# STM32MP23_CM33 register map
File version: 1.2
CPU: CM33 r0p1, little endian, MPU, FPU, vendor SysTick, 8 interrupt priority bits
Registers are 32-bit, read-write, reset 0x0 unless marked. A register's access mark holds for its fields unless they carry their own. Offsets are from the block's base; [hi:lo] are bit positions; 'fields as' and 'values as' point back to an identical list.

## USB3DR (part 3 of 4) — USB3DR register block
Base 0x48300000
Same registers: USB3DR_S 0x58300000
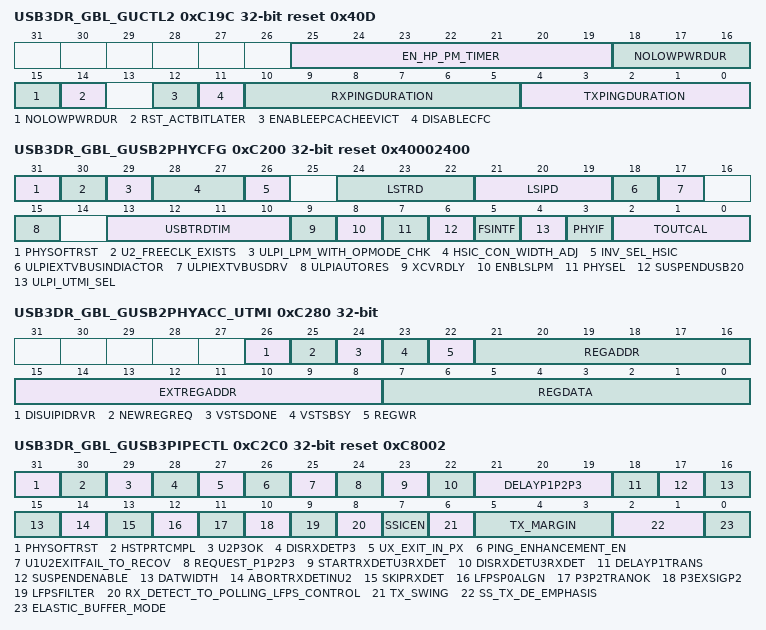
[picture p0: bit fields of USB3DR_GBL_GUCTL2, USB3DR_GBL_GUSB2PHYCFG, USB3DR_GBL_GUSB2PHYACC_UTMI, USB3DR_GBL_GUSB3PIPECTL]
0xC19C USB3DR_GBL_GUCTL2 reset 0x40D — USB3DR global user control register 2
  [25:19] EN_HP_PM_TIMER — This register field is used to set new HP and PM timers. - To enable PM timer, set GUCTL2[19] bit as 1. - To enable HP timer, set GUCTL2[20] bit as 1. Default value is 4 us, when new HP timer is enabled default value is 11 us. Use GUCTL2[25:21] to specify HP timer value in microseconds.
  [18:15] NOLOWPWRDUR — No low power duration (NOLOWPWRDUR) This bit is applicable for Device mode only and is ignored in Host mode. After starting a transfer on an ESS ISOC endpoint, the application must program these bits. Each count represents the duration in terms of milliseconds. For example, a value of 3 represents 3ms.
  [14] RST_ACTBITLATER — Enable clearing of the command active bit for the ENDXFER command after the command execution is completed. This bit is valid in device mode only.
  [12] ENABLEEPCACHEEVICT — Enable evicting endpoint cache after flow control for bulk endpoints. In 3.00a release, a performance enhancement was done to keep the non-stream capable bulk IN endpoint in cache after flow control. Setting this bit disables this enhancement. Thismust be set only for debug purpose.
  [11] DISABLECFC — Disable xHCI errata feature contiguous frame ID capability This field controls the xHCI errata feature contiguous FrameID capability. When set, the xHCI HCCPARAMS1 bit 11 is set to 0 indicating that CFC is not supported. Disable this feature only if the application cannot tolerate missed service error events for Isoc transfers, and the system latencies are large enough to cause missed service errors even if the software is following the isochronous thresholding rules.
  [10:5] RXPINGDURATION — Receive ping maximum duration This field is relevant in Host mode and controls the maximum duration of received LFPS to be treated as a ping LFPS. The maximum duration of the ping LFPS is controlled by programming this value by steps of 8ns. Example: A value of 32 indicates 256ns.
  [4:0] TXPINGDURATION — Transmit ping maximum duration This field is relevant in Device mode and controls the maximum duration for which the controller should instruct the PHY to transmit a ping LFPS. The duration of the ping LFPS is controlled by programming this value by steps of 8ns. Example: A value of 13 indicates 104ns.
0xC200 USB3DR_GBL_GUSB2PHYCFG reset 0x40002400 — USB3DR global USB2 PHY configuration register
  [31] PHYSOFTRST — UTMI PHY soft reset (PHYSoftRst) Causes the usb2phy_reset signal to be asserted to reset a UTMI PHY. Not applicable to ULPI because ULPI PHYs are reset via their FunctionControl.Reset register, and the core automatically writes to this register when the core is reset (vcc_reset_n, USBCMD.HCRST, DCTL.SoftReset, or GCTL.SoftReset)
  [30] U2_FREECLK_EXISTS — U2_FREECLK_EXISTS Specifies whether the USB 2.0 PHY provides a free-running PHY clock, which is active when the clock control input is active. If the USB 2.0 PHY provides a free-running PHY clock, it must be connected to the utmi_clk[0] input. The remaining utmi_clk[n] must be connected to the respective port clocks. The core uses the Port-0 clock for generating the internal mac2 clock. Note: When the core is configured as device-only (USB3DR_MODE=0), do not set this bit to 1.
    0=USB 2.0 free clock does not exist; 1=USB 2.0 free clock exists
  [29] ULPI_LPM_WITH_OPMODE_CHK — ULPI_LPM_WITH_OPMODE_CHK Support the LPM over ULPI without NOPID token to the ULPI PHY. If this bit is set, the ULPI PHY is expected to qualify the EXT PID with OPMODE=0b00 for LPM and not treat it as a NOPID. Check the PHY behavior with the vendor. This bit is valid only when the USB3DR_HSPHY_INTERFACE parameter is 2 or 3. Note: This bit is valid only in Host mode. This bit should be 0 for Synopsys PHY.
    0=A NOPID is sent before sending an EXTPID for LPM; 1=An EXTPID is sent without previously sending a NOPID
  [28:27] HSIC_CON_WIDTH_ADJ ro — HSIC_CON_WIDTH_ADJ This bit is used in the HSIC device mode of operation. By default, the connect duration for the HSIC device controller is thrice the strobe period. This duration can be changed to 4, 5, or 6 times the strobe period by setting the value of this field to 1, 2, or 3. This value is added to the default connect duration.
  [26] INV_SEL_HSIC ro — INV_SEL_HSIC The application driver uses this bit to control the HSIC enable/disable function. When set to 1, this bit overrides and functionally inverts the 'if_select_hsic' input signal. If 1213417795 is: If the controller operates as non-HSIC-capable, it can only connect to non-HSIC-capable PHYs. If it operates as HSIC-capable, it can connect to HSIC-capable PHYs. This bit is reserved if the USB3DR_ENABLE_HSIC parameter is set to 0. When selecting the HSIC feature, set the host side to HSIC mode first, then set the device mode side. If the device side is set to HSIC mode first and if the host does not see a connection in HSIC mode, the device HSIC mode must be deselected and selected again using the if_select_hsic setting or register bit GUSB2PHYCFGn[26] to ensure that the device can connect to the host.
    0=HSIC Capability is disabled; 1=HSIC Capability is enabled
  [24:22] LSTRD — LS Turnaround Time (LSTRDTIM) This field indicates the value of the RX-to-TX packet gap for LS devices. The encoding is as follows: Note: This field is applicable only in Host mode. Note: For normal operation (to work with most LS devices), set the default value of this field to 0 (2 bit times). Note: The programmable LS device inter-packet gap and turnaround delays are provided to support some legacy LS devices that might require different delays than the default/fixed ones. For instance, the open LS mouse requires 3 bit times of inter-packet gap to work correctly. Note: Include the PHY delays when programming the LSIPD/LSTRDTIM values. For example, if the PHY's TxEndDelay in LS mode is 30 UTMI/ULPI CLKs, then subtract this delay (~1 LS bit time) from the device's delay requirement.
    0=2 bit times; 1=2.5 bit times
  [21:19] LSIPD — LS Inter-Packet Time (LSIPD) This field indicates the value of TX-to-TX packet gap for LS devices. The encoding is as follows: Note: This field is applicable only in Host mode. Note: For normal operation (to work with most LS devices), set the default value of this field to 2 (3 bit times). Note: The programmable LS device inter-packet gap and turnaround delays are provided to support some legacy LS devices that might require different delays than the default/fixed ones. For instance, the AOpen LS mouse requires 3 bit times of inter-packet gap to work correctly. Note: Include the PHY delays when programming the LSIPD/LSTRDTIM values. For example, if the PHY's TxEndDelay in LS mode is 30 UTMI/ULPI CLKs, then subtract this delay (~1 LS bit time) from the device's delay requirement.
    0=2 bit times; 1=2.5 bit times
  [18] ULPIEXTVBUSINDIACTOR — ULPI external VBUS indicator (ULPIExtVbusIndicator) Indicates the ULPI PHY VBUS over-current indicator. Valid only when RTL parameter USB3DR_HSPHY_INTERFACE=2 or 3
    0=PHY uses an internal VBUS valid comparator; 1=PHY uses an external VBUS valid comparator
  [17] ULPIEXTVBUSDRV — ULPI external VBUS drive (ULPIExtVbusDrv) Selects supply source to drive 5V on VBUS, in the ULPI PHY. (Only when RTL parameter USB3DR_HSPHY_INTERFACE=2 or 3)
    0=PHY drives VBUS with internal charge pump (default); 1=PHY drives VBUS with an external supply
  [15] ULPIAUTORES — ULPI auto resume (ULPIAutoRes) Sets the AutoResume bit in interface control register on the ULPI PHY. Valid only when RTL parameter USB3DR_HSPHY_INTERFACE=2 or 3
    0=PHY does not use the AutoResume feature; 1=PHY uses the AutoResume feature
  [13:10] USBTRDTIM — USB 2.0 turnaround time (USBTrdTim) Sets the turnaround time in PHY clocks. Specifies the response time for a MAC request to the packet FIFO controller (PFC) to fetch data from the DFIFO (SPRAM). The following are the required values for the minimum device bus frequency of 60MHz. USB turnaround time is a critical certification criteria when using long cables and five hub levels. The required values for this field: If device bus clock is less than 60MHz, and USB turnaround time is not critical, this field can be set to a larger value. Note: This field is valid only in device mode.
    5=When the MAC interface is 16-bit UTMI+; 9=When the MAC interface is 8-bit UTMI+/ULPI
  [9] XCVRDLY — Transceiver Delay: Enables a delay between the assertion of the UTMI/ULPI transceiver select signal (for HS) and the assertion of the TxValid signal during a HS Chirp. When this bit is set to 1, a delay (of approximately 2.5 us) is introduced from the time when the transceiver select is set to 0b00 (HS) to the time the TxValid is driven to 0 for sending the chirp-K. This delay is required for some UTMI/ULPI PHYs. Note: If the hibernation feature is enabled when the device core comes out of power-off, this bit must be re-initialized with the appropriate value because the core does not save and restore this bit value during hibernation. Note: This bit is valid only in device mode.
  [8] ENBLSLPM — Enable utmi_sleep_n and utmi_l1_suspend_n (EnblSlpM) The application uses this bit to control utmi_sleep_n and utmi_l1_suspend_n assertion to the PHY in the L1 state. Note: This bit must be set high for Port0 if Synopsys PHY is used. Note: In Device mode, before issuing any device endpoint command when operating in 2.0 speeds, disable this bit and enable it after the command completes. Without disabling this bit, if a command is issued when the device is in L1 state and if mac2_clk (utmi_clk/ulpi_clk) is gated off, the command is not completed.
    0=utmi_sleep_n and utmi_l1_suspend_n assertion from the core is not transferred to the external PHY; 1=utmi_sleep_n and utmi_l1_suspend_n assertion from the core is transferred to the external PHY
  [7] PHYSEL wo — USB 2.0 high-speed PHY or USB 1.1 full-speed serial transceiver select The application uses this bit to select a high-speed PHY or a full-speed transceiver. If both interface types are selected in coreConsultant (that is, parameters values are not zero), the application uses this bit to select the active interface, with read-write bit access. Note: USB 1.1 full-serial transceiver is not supported. This bit always reads as 0.
    0=USB 2.0 high-speed UTMI+ or ULPI PHY. This bit is always 0, with write only access.; 1=USB 1.1 full-speed serial transceiver. This bit is always 1, with write only access.
  [6] SUSPENDUSB20 — Suspend USB2.0 HS/FS/LS PHY (SusPHY) When set, USB2.0 PHY enters Suspend mode if suspend conditions are valid. For DRD/OTG configurations, it is recommended that this bit is set to 0 during coreConsultant configuration. If it is set to 1, then the application must clear this bit after power-on reset. Application needs to set it to 1 after the core initialization completes. For all other configurations, this bit can be set to 1 during core configuration. Note: In Host mode, on reset, this bit is set to 1. Software can override this bit after reset. Note: In device mode, before issuing any device endpoint command when operating in 2.0 speeds, disable this bit and enable it after the command completes. If a command is issued without disabling this bit when the device is in L2 state and if mac2_clk (utmi_clk/ulpi_clk) is gated off, the command is not completed.
  [5] FSINTF ro — Full-Speed serial interface select (FSIntf) The application uses this bit to select a unidirectional or bidirectional USB 1.1 full-speed serial transceiver interface. Note: USB 1.1 full-speed serial interface is not supported. This bit always reads as 0.
    0=6-pin unidirectional full-speed serial interface. This bit is set to 0 with read only access.; 1=3-pin bidirectional full-speed serial interface. This bit is set to 0 with read only access.
  [4] ULPI_UTMI_SEL ro — ULPI or UTMI+ select (ULPI_UTMI_Sel) The application uses this bit to select a UTMI+ or ULPI interface. This bit is writable only if UTMI+ and ULPI is specified for high-speed PHY interface(s) in coreConsultant configuration (USB3DR_HSPHY_INTERFACE=3). Otherwise, this bit is read-only and the value depends on the interface selected through USB3DR_HSPHY_INTERFACE.
    0=UTMI+ interface; 1=ULPI interface
  [3] PHYIF — PHY interface (PHYIf) If UTMI+ is selected, the application uses this bit to configure the core to support a UTMI+ PHY with an 8- or 16-bit interface. ULPI mode: 0 Note: All the enabled 2.0 ports must have the same clock frequency as Port0 clock frequency (utmi_clk[0]). Note: The UTMI 8-bit and 16-bit modes cannot be used together for different ports at the same time (that is, all the ports must be in 8-bit mode, or all of them must be in 16-bit mode, at a time). Note: If any of the USB 2.0 ports is selected as ULPI port for operation, then all the USB 2.0 ports must be operating at 60MHz.
    0=8 bits; 1=16 bits
  [2:0] TOUTCAL — HS/FS timeout calibration (TOutCal) The number of PHY clocks, as indicated by the application in this field, is multiplied by a bit-time factor; this factor is added to the high-speed/full-speed interpacket timeout duration in the core to account for additional delays introduced by the PHY. This may be required, since the delay introduced by the PHY in generating the linestate condition may vary among PHYs. The USB standard timeout value for high-speed operation is 736 to 816 (inclusive) bit times. The USB standard timeout value for full-speed operation is 16 to 18 (inclusive) bit times. The application must program this field based on the speed of connection. The number of bit times added per PHY clock are: High-speed operation: One 30MHz PHY clock=16 bit times One 60MHz PHY clock=8 bit times Full-speed operation: One 30MHz PHY clock=0.4 bit times One 60MHz PHY clock=0.2 bit times One 48MHz PHY clock=0.25 bit times
0xC280 USB3DR_GBL_GUSB2PHYACC_UTMI ro — USB3DR global USB 2.0 UTMI PHY vendor control register
  [26] DISUIPIDRVR
  [25] NEWREGREQ — New register request The application sets this bit for a new vendor control access. Setting this bit to 1 asserts the utmi_vcontrolload_n (0b0) on the UTMI interface.
  [24] VSTSDONE
  [23] VSTSBSY
  [22] REGWR — Register write The application sets this bit for register writes and clears it for register reads. Note: This bit is applicable for ULPI register read/write access only.
  [21:16] REGADDR — Register address The 6-bit PHY register address for immediate PHY register set access. Set to 0x2F for extended PHY register set access. Note: These bits are applicable for ULPI only.
  [15:8] EXTREGADDR
  [7:0] REGDATA
0xC2C0 USB3DR_GBL_GUSB3PIPECTL reset 0xC8002 — USB3DR global USB 3.0 PIPE control register
  [31] PHYSOFTRST — USB3 PHY soft reset After setting this bit to 1, the software needs to clear this bit.
  [30] HSTPRTCMPL — HstPrtCmpl This feature tests the PIPE PHY compliance patterns without having to have a test fixture on the USB 3.0 cable. This bit enables placing the SS port link into a compliance state. By default, this bit must be set to 0. In compliance lab testing, the SS port link enters compliance after failing the first polling sequence after power on. Set this bit to 0, when compliance tests are executed. The sequence for using this functionality is as follows: Disconnect any plugged in devices. Perform USBCMD.HCRST or power-on-chip reset. Set PORTSC.PLS=0xA. Set PORTSC.PP=0. Set GUSB3PIPECTL. HstPrtCmpl=1. This places the link into compliance state. To advance the compliance pattern, follow this sequence (toggle the set GUSB3PIPECTL. HstPrtCmpl): Set GUSB3PIPECTL.HstPrtCmpl=0. Set GUSB3PIPECTL.HstPrtCmpl=1. This advances the link to the next compliance pattern. To exit from the compliance state perform USBCMD.HCRST or power-on-chip reset.
  [29] U2P3OK — P3 OK for U2 (u2P3ok) Note: For a port, if GUSB3PIPECTL[7]=1 and GUSB3PIPECTL[29]=1, set GUSB3PIPECTL[11] to 1.
    0=During link state U2/SS.Inactive, put PHY in P2 (default); 1=During link state U2/SS.Inactive, put PHY in P3
  [28] DISRXDETP3 — Disabled receiver detection in P3 (DisRxDetP3)
    0=If PHY is in P3 and the core needs to perform receiver detection, the core performs receiver detection in P3 (default); 1=If PHY is in P3 and the core needs to perform receiver detection, the core changes the PHY power state to P2 and then performs receiver detection. After receiver detection, the cores changes PHY power state to P3.
  [27] UX_EXIT_IN_PX — Ux exit in Px (Ux_exit_in_Px) Note: This bit is used by third party SS PHY. It must be set to 0 for Synopsys PHY.
    0=The core does U1/U2/U3 exit in PHY power state P0 (default behavior); 1=The core does U1/U2/U3 exit in PHY power state P1/P2/P3 respectively
  [26] PING_ENHANCEMENT_EN — Ping enhancement enable (ping_enhancement_en) When set, the downstream port U1 ping receive timeout becomes 500ms instead of 300ms. Minimum Ping.LFPS receive duration is 8ns (one mac3_clk). This field is valid for the downstream port only. Note: This bit is used by third party SS PHY. It must be set to 0 for Synopsys PHY.
  [25] U1U2EXITFAIL_TO_RECOV — U1U2exitfail to recovery (u1u2exitfail_to_recov) When set, and U1/U2 LFPS handshake fails, the LTSSM transitions from U1/U2 to recovery instead of SS inactive. If recovery fails, then the LTSSM can enter SS.Inactive. This is an enhancement only. It prevents interoperability issue if the remote link does not do proper handshake.
  [24] REQUEST_P1P2P3 — Always request P1/P2/P3 for U1/U2/U3 (request_p1p2p3) When set, the core always requests PHY power change from P0 to P1/P2/P3 during U0 to U1/U2/U3 transition. If this bit is 0, and immediate Ux exit happens (remotely initiated, or locally initiated), the core does not request P1/P2/P3 power state change. Note: This bit must be set to 1 for Synopsys PHY. For third party SS PHY, check with the PHY vendor.
  [23] STARTRXDETU3RXDET wo — Start receiver detection in U3/RX.Detect (StartRxdetU3RxDet) If USB3DR_GUSB3PIPECTL_INIT[22] is set, and the link is in either U3 or RX.Detect state, the core starts receiver detection on the rising edge of this bit. This can only be used for downstream ports. This bit must be set to 0 for upstream ports. This feature must not be enabled for normal operation. If this feature must be used, contact Synopsys.
  [22] DISRXDETU3RXDET — Disable receiver detection in U3/RX.Det When set, the core does not handle receiver detection in either U3 or RX.Detect states. USB3DR_GUSB3PIPECTL_INIT[23] must be used to start receiver detection manually. This bit can only be used for the downstream port. This bit must be set to 0 for upstream ports. This feature must not be enabled for normal operation. If this feature must be used, contact Synopsys.
  [21:19] DELAYP1P2P3 — Delay P1P2P3 Delay P0 to P1/P2/P3 request when entering U1/U2/U3 until (USB3DR_GUSB3PIPECTL_INIT[21:19]*8) 8B10B error occurs, or Pipe3_RxValid drops to 0. USB3DR_GUSB3PIPECTL_INIT[18] must be 1 to enable this functionality.
  [18] DELAYP1TRANS — Delay PHY power change from P0 to P1/P2/P3 when link state changing from U0 to U1/U2/U3 respectively. Note: If the Synopsys PHY is used, contact Synopsys customer support for recommendation on setting this bit because it is node dependent. Note: If a third party SS PHY is used, check with the PHY vendor for recommendation on setting this bit.
    1=When entering U1/U2/U3, delay the transition to P1/P2/P3 until the pipe3 signals, Pipe3_RxElecIdle is 1 and pipe3_RxValid is 0; 0=When entering U1/U2/U3, transition to P1/P2/P3 without checking for Pipe3_RxElecIdle and pipe3_RxValid
  [17] SUSPENDENABLE — Suspend USB3.0 SS PHY (Suspend_en) When set, and if suspend conditions are valid, the USB 3.0 PHY enters Suspend mode. For DRD/OTG configurations, it is recommended that this bit is set to 0 during coreConsultant configuration. If it is set to 1, then the application must clear this bit after power-on reset. Application needs to set it to 1 after the core initialization is completed. For all other configurations, this bit can be set to 1 during core configuration.
  [16:15] DATWIDTH ro — PIPE data width (DatWidth) One clock after reset, these bits receive the value seen on the pipe3_DataBusWidth. The simulation test bench uses the coreConsultant parameter to configure the VIP. These bits in the coreConsultant parameter must match the PHY data width and the pipe3_DataBusWidth port.
    0=32 bits; 1=16 bits; 2=8 bits
  [14] ABORTRXDETINU2 — Abort RX detect in U2 (AbortRxDetInU2) When set, and the link state is U2, then the core aborts the receiver detection if it receives U2 exit LFPS from the remote link partner. This bit is for the downstream port only. Note: This bit is used by third party SS PHY. It must be set to 0 for Synopsys PHY.
  [13] SKIPRXDET — Skip RX detect: When set, the core skips RX detection if pipe3_RxElecIdle is low. Skip is defined as waiting for the appropriate timeout, then repeating the operation.
  [12] LFPSP0ALGN — LFPS P0 Align: When set, The core deasserts LFPS transmission on the clock edge that it requests Phy power state 0 when exiting U1, U2, or U3 low power states. Otherwise, LFPS transmission is asserted one clock earlier. The core requests symbol transmission two pipe3_rx_pclks periods after the PHY asserts PhyStatus as a result of the PHY switching from P1 or P2 state to P0 state. Currently, this bit is only used in USB 3.0 HUB with Synopsys PHY. For other USB 3.0 Host, Device, and DRD cores, this bit is not required.
  [11] P3P2TRANOK — P3 P2 transitions OK (P3P2TranOK) When set, the core transitions directly from Phy power state P2 to P3 or from state P3 to P2. When not set, P0 is always entered as an intermediate state during transitions between P2 and P3, as defined in [PIPE]. According to [PIPE], any direct transition between P3 and P2 is illegal. Note: This bit is used by third party SS PHY. It must be set to 0 for Synopsys PHY.
  [10] P3EXSIGP2 — P3 exit signal in P2 (P3ExSigP2) When this bit is set, the core always changes the PHY power state to P2, before attempting a U3 exit handshake. This bit is used only for some non-Synopsys PHYs that cannot do LFPS in P3. Note: This bit is used by third party SS PHY. It must be set to 0 for Synopsys PHY.
  [9] LFPSFILTER — LFPS filter (LFPSFilt) When set, filters LFPS reception with pipe3_RxValid in PHY power state P0, that is, ignores LFPS reception from the PHY unless both pipe3_Rxelecidle and pipe3_RxValid are deasserted.
  [8] RX_DETECT_TO_POLLING_LFPS_CONTROL — RX_DETECT to Polling.LFPS control During controller certification with third party PHY it is observed that the PHY is not able to meet the TX AC common mode voltage active (VTX-CM-ACPP_ACTIVE 100 mV) if the link starts polling within 80 us from the time rx.detect is performed. To meet this VTX-CM-ACPP_ACTIVE specification, the polling must be delayed further. If the PHY does not have issue, then one can set this bit to 1 which allows polling to start within 80 us.
    0=Default (Enables a 400 us delay to start polling LFPS after RX_DETECT. This allows VCM offset to settle to a proper level.); 1=Disables the 400 us delay to start polling LFPS after RX_DETECT
  [7] SSICEN — USB3 SSIC enable (SSICEn) This bit is valid only when coreConsultant parameter USB3DR_EN_SSIC=1 else this bit needs to be set to 0. Note: When the USB3DR_NUM_SSIC_PORTS parameter is set to zero, the access type of this register bit is R_W, but the register bit is not functional.
    0=Pipe interface is active. The RMMI interface on the corresponding port is reset by the core.; 1=RMMI interface on the corresponding port connected to M-PHY is active, and pipe interface is inactive. This bit needs to be set before accessing the corresponding GUSB3RMMICTLn register.
  [6] TX_SWING — TX swing (TxSwing) Refer to [PIPE].
  [5:3] TX_MARGIN — TX Margin[2:0] (TxMargin) Refer to Table 5-3 of [PIPE]
  [2:1] SS_TX_DE_EMPHASIS — TX deemphasis (TxDeemphasis) The value driven to the PHY is controlled by the LTSSM during USB3 Compliance mode. (Refer to Table 5-3 of [PIPE].)
  [0] ELASTIC_BUFFER_MODE — Elastic buffer mode (ElasticBufferMode) (Refer to Table 5-3 of [PIPE].)
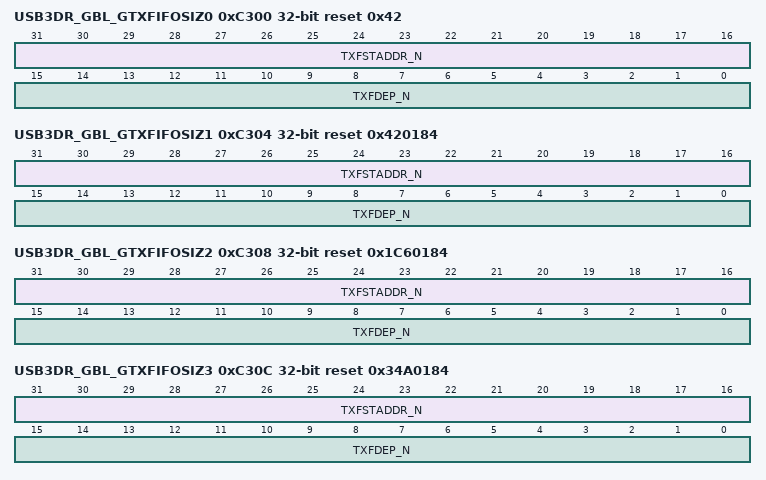
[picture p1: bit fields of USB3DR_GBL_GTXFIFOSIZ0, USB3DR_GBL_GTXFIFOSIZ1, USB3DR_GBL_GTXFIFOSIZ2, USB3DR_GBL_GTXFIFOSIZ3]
0xC300 USB3DR_GBL_GTXFIFOSIZ0 reset 0x42 — USB3DR global transmit FIFO size register 0
  [31:16] TXFSTADDR_N — Transmit FIFOn RAM start address This field contains the memory start address for TxFIFOn in MDWIDTH-bit words.
  [15:0] TXFDEP_N — TxFIFO depth This field contains the depth of TxFIFOn in MDWIDTH-bit words. Minimum value: 32 Maximum value: 32,768
0xC304 USB3DR_GBL_GTXFIFOSIZ1 reset 0x420184 — USB3DR global transmit FIFO size register 1 GTXFIFOSIZ 1
  [31:16] TXFSTADDR_N — Transmit FIFOn RAM start address This field contains the memory start address for TxFIFOn in MDWIDTH-bit words.
  [15:0] TXFDEP_N
0xC308 USB3DR_GBL_GTXFIFOSIZ2 reset 0x1C60184 — USB3DR global transmit FIFO size register 2
  fields as USB3DR_GBL_GTXFIFOSIZ0
0xC30C USB3DR_GBL_GTXFIFOSIZ3 reset 0x34A0184 — USB3DR global transmit FIFO size register 3
  [31:16] TXFSTADDR_N — transmit FIFOn RAM start address This field contains the memory start address for TxFIFOn in MDWIDTH-bit words.
  [15:0] TXFDEP_N — TxFIFO depth (TxFDep_n) This field contains the depth of TxFIFOn in MDWIDTH-bit words. Minimum value: 32 Maximum value: 32,768
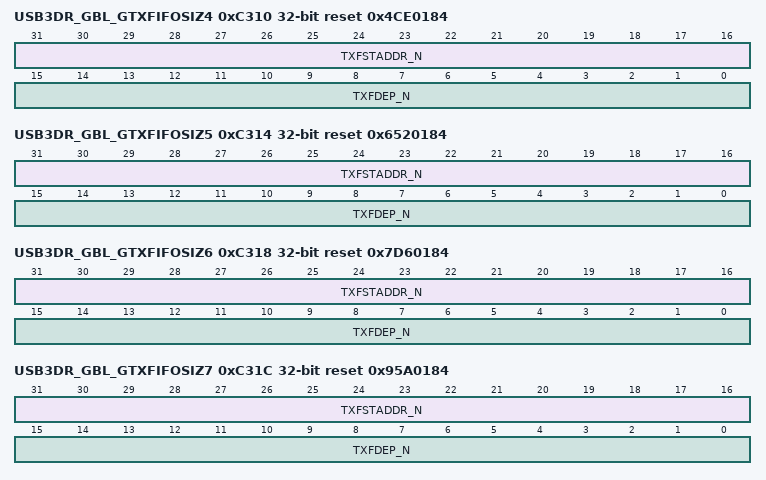
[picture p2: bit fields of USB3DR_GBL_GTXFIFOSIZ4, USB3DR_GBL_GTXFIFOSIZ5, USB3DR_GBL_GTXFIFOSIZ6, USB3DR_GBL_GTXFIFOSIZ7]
0xC310 USB3DR_GBL_GTXFIFOSIZ4 reset 0x4CE0184 — USB3DR global transmit FIFO size register 4
  [31:16] TXFSTADDR_N
  [15:0] TXFDEP_N — TXFDEP_N: TxFIFO depth (TxFDep_n) This field contains the depth of TxFIFOn in MDWIDTH-bit words. Minimum value: 32 Maximum value: 32,768
0xC314 USB3DR_GBL_GTXFIFOSIZ5 reset 0x6520184 — USB3DR global transmit FIFO size register 5
  [31:16] TXFSTADDR_N — Transmit FIFOn RAM start address
  [15:0] TXFDEP_N — TxFIFO depth This field contains the depth of TxFIFOn in MDWIDTH-bit words. Minimum value: 32 Maximum value: 32,768
0xC318 USB3DR_GBL_GTXFIFOSIZ6 reset 0x7D60184 — USB3DR global transmit FIFO size register 6
  fields as USB3DR_GBL_GTXFIFOSIZ0
0xC31C USB3DR_GBL_GTXFIFOSIZ7 reset 0x95A0184 — USB3DR global transmit FIFO size register 7
  fields as USB3DR_GBL_GTXFIFOSIZ0
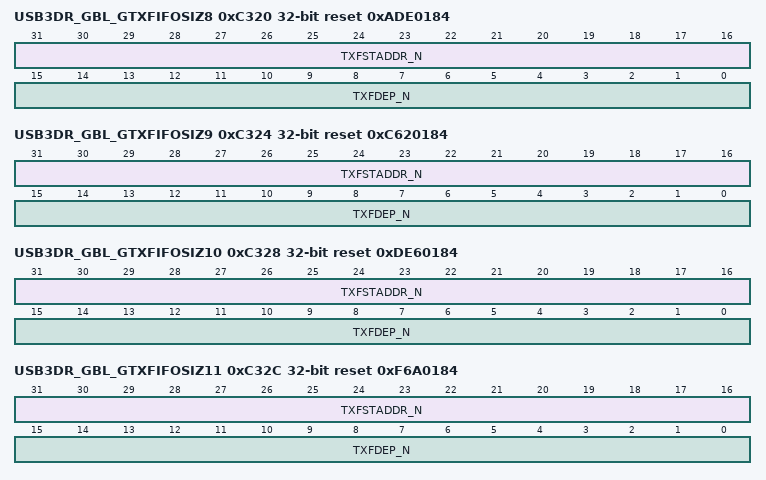
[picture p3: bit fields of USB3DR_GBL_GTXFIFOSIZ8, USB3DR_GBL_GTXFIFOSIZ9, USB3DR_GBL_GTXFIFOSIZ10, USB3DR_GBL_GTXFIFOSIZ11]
0xC320 USB3DR_GBL_GTXFIFOSIZ8 reset 0xADE0184 — USB3DR global transmit FIFO size register 8
  fields as USB3DR_GBL_GTXFIFOSIZ0
0xC324 USB3DR_GBL_GTXFIFOSIZ9 reset 0xC620184 — USB3DR global transmit FIFO size register 9
  fields as USB3DR_GBL_GTXFIFOSIZ0
0xC328 USB3DR_GBL_GTXFIFOSIZ10 reset 0xDE60184 — USB3DR global transmit FIFO size register 10
  [31:16] TXFSTADDR_N — Transmit FIFOn RAM Start address This field contains the memory start address for TxFIFOn in MDWIDTH-bit words.
  [15:0] TXFDEP_N — TxFIFO depth (TxFDep_n) This field contains the depth of TxFIFOn in MDWIDTH-bit words. Minimum value: 32 Maximum value: 32,768
0xC32C USB3DR_GBL_GTXFIFOSIZ11 reset 0xF6A0184 — USB3DR global transmit FIFO size register 11
  fields as USB3DR_GBL_GTXFIFOSIZ0
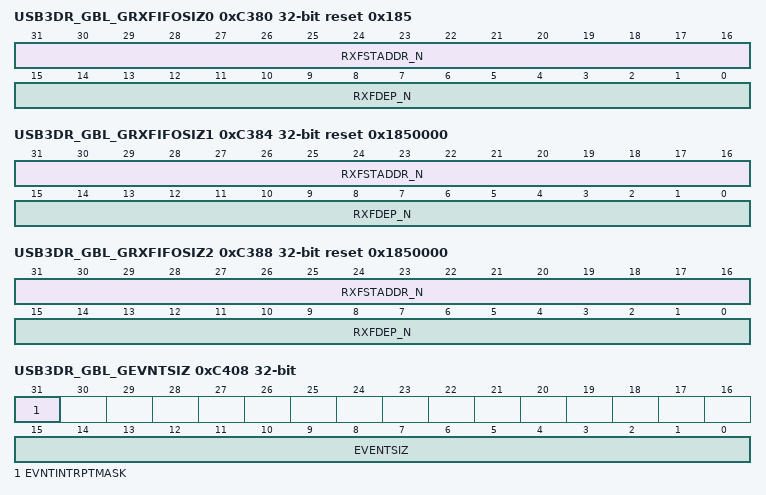
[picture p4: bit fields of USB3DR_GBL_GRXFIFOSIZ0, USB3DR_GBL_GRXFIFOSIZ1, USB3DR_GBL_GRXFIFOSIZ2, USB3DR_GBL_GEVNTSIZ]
0xC380 USB3DR_GBL_GRXFIFOSIZ0 reset 0x185 — USB3DR global receive FIFO size register 0
  [31:16] RXFSTADDR_N — RxFIFOn RAM start address (RxFStAddr_n) This field contains the memory start address for RxFIFOn in MDWIDTH-bit words.
  [15:0] RXFDEP_N — RxFIFO depth (RxFDep_n) This field contains the depth of RxFIFOn in MDWIDTH-bit words. Minimum value: 32 Maximum value: 16,384
0xC384 USB3DR_GBL_GRXFIFOSIZ1 reset 0x1850000 — USB3DR global receive FIFO size register 1
  [31:16] RXFSTADDR_N
  [15:0] RXFDEP_N — RxFIFO depth This field contains the depth of RxFIFOn in MDWIDTH-bit words. Minimum value: 32 Maximum value: 16,384
0xC388 USB3DR_GBL_GRXFIFOSIZ2 reset 0x1850000 — USB3DR global receive FIFO size register 2
  fields as USB3DR_GBL_GRXFIFOSIZ1
0xC400 USB3DR_GBL_GEVNTADRLO — USB3DR global event buffer address low register
  [31:0] EVNTADRLO — Event buffer address (EvntAdrLo) Holds the lower 32 bits of start address of the external memory for the event buffer. During operation, hardware does not update this address.
0xC404 USB3DR_GBL_GEVNTADRHI — USB3DR global event buffer address high register
  [31:0] EVNTADRHI — Event buffer address (EvntAdrHi) Holds the higher 32 bits of start address of the external memory for the event buffer. During operation, hardware does not update this address.
0xC408 USB3DR_GBL_GEVNTSIZ (reset mask 0x7FFF0000) — USB3DR global event buffer size register
  [31] EVNTINTRPTMASK — Event interrupt mask (EvntIntMask). When set to 1, this prevents the interrupt from being generated. However, even when the mask is set, the events are queued.
  [15:0] EVENTSIZ — Event buffer size in bytes (EVNTSiz) Holds the size of the event buffer in bytes; must be a multiple of four. This is programmed by software once during initialization. The minimum size of the event buffer is 32 bytes.
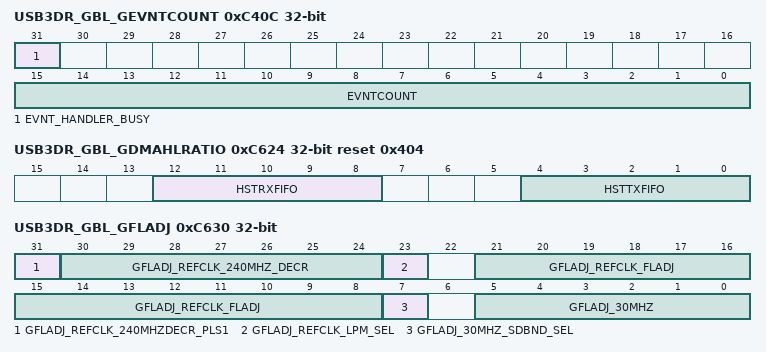
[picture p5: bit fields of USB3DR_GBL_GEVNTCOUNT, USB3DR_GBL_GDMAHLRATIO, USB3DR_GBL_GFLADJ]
0xC40C USB3DR_GBL_GEVNTCOUNT — USB3DR global event buffer count register
  [31] EVNT_HANDLER_BUSY — Event handler busy Device software event handler busy indication. The controller sets this bit when the interrupt line is asserted due to pending events. Software clears this bit (with 1) when it has finished processing the events (along with updating the EVNTCOUNT in this register). The controller does not raise the interrupt line for a new event unless this bit is cleared. Note: When interrupt moderation is disabled (that is, DEVICE_IMODI=0), this bit is ignored.
  [15:0] EVNTCOUNT — Event count (EVNTCount) When read, returns the number of valid events in the event buffer (in bytes). When written, hardware decrements the count by the written value. When interrupt moderation is enabled (that is, DEVICE_IMODI different 0), the interrupt line gets de-asserted when the first write happens on this register to decrement the count. When interrupt moderation is disabled (that is, DEVICE_IMODI = 0), the interrupt line continues to get asserted until the event count becomes zero (no-moderation behavior).
0xC600 USB3DR_GBL_GHWPARAMS8 ro reset 0x7EC — USB3DR global hardware parameters register 8
  [31:0] GHWPARAMS8_32_0 — USB3DR_DCACHE_DEPTH_INFO
0xC610 USB3DR_GBL_GTXFIFOPRIDEV — USB3DR global device TX FIFO DMA priority register
  [11:0] GTXFIFOPRIDEV — Device TxFIFO priority
0xC618 USB3DR_GBL_GTXFIFOPRIHST — USB3DR global host TX FIFO DMA priority register
  [2:0] GTXFIFOPRIHST — Host TxFIFO priority
0xC61C USB3DR_GBL_GRXFIFOPRIHST — USB3DR global host RX FIFO DMA priority register
  [2:0] GRXFIFOPRIHST — Host RxFIFO priority
0xC624 USB3DR_GBL_GDMAHLRATIO reset 0x404 — USB3DR global host FIFO DMA high-low priority ratio register
  [12:8] HSTRXFIFO — Host RXFIFO DMA high-low priority
  [4:0] HSTTXFIFO — Host TXFIFO DMA high-low priority
0xC630 USB3DR_GBL_GFLADJ — USB3DR global frame length adjustment register
  [31] GFLADJ_REFCLK_240MHZDECR_PLS1 — GFLADJ_REFCLK_240MHZDECR_PLS1 This field indicates that the decrement value that the controller applies for each ref_clk must be GFLADJ_REFCLK_240MHZ_DECR and GFLADJ_REFCLK_240MHZ_DECR +1 alternatively on each ref_clk. Set this bit to a 1 only if GFLADJ_REFCLK_LPM_SEL is set to '1' and the fractional component of 240/ref_frequency is greater than or equal to 0.5. Examples: If the ref_clk is 19.2MHz then GUCTL.REF_CLK_PERIOD=52 GFLADJ.GFLADJ_REFCLK_240MHZ_DECR=(240/19.2)=12.5 GFLADJ.GFLADJ_REFCLK_240MHZDECR_PLS1=1 If the ref_clk is 24MHz then GUCTL.REF_CLK_PERIOD=41 GFLADJ.GFLADJ_REFCLK_240MHZ_DECR=(240/24)=10 GFLADJ.GFLADJ_REFCLK_240MHZDECR_PLS1=0
  [30:24] GFLADJ_REFCLK_240MHZ_DECR — This field indicates the decrement value that the controller applies for each ref_clk in order to derive a frame timer in terms of a 240MHz clock. This field must be programmed to a non-zero value only if GFLADJ_REFCLK_LPM_SEL is set to 1. The value is derived as follows: GFLADJ_REFCLK_240MHZ_DECR=240/ref_clk_frequency Examples: If the ref_clk is 24MHz then GUCTL.REF_CLK_PERIOD=41 GFLADJ.GFLADJ_REFCLK_240MHZ_DECR=240/24=10 If the ref_clk is 48MHz then GUCTL.REF_CLK_PERIOD=20 GFLADJ.GFLADJ_REFCLK_240MHZ_DECR=240/48=5 If the ref_clk is 17MHz then GUCTL.REF_CLK_PERIOD=58 GFLADJ.GFLADJ_REFCLK_240MHZ_DECR=240/17=14
  [23] GFLADJ_REFCLK_LPM_SEL — This bit enables the functionality of running SOF/ITP counters on the ref_clk. This bit must not be set to 1 if GCTL.SOFITPSYNC bit is set to 1. Similarly, if GFLADJ_REFCLK_LPM_SEL set to 1, GCTL.SOFITPSYNC must not be set to 1. When GFLADJ_REFCLK_LPM_SEL is set to 1 the overloading of the suspend control of the USB 2.0 first port PHY (UTMI/ULPI) with USB 3.0 port states is removed. For example, for Synopsys PHY, the COMMONONN signal can be tied to 1. Note: The ref_clk frequencies supported in this mode are 16/17/19.2/20/24/39.7/40 MHz. The utmi_clk[0] signal of the core must be connected to the FREECLK of the PHY. Note: If this bit is set to 1, the GUSB2PHYCFG.U2_FREECLK_EXISTS bit must be set to 0.
  [21:8] GFLADJ_REFCLK_FLADJ — This field indicates the frame length adjustment to be applied when SOF/ITP counter is running on the ref_clk. This register value is used to adjust the ITP interval when GCTL[SOFITPSYNC] is set to '1'; SOF and ITP interval when GLADJ.GFLADJ_REFCLK_LPM_SEL is set to '1'. This field must be programmed to a non-zero value only if GFLADJ_REFCLK_LPM_SEL is set to 1 or GCTL.SOFITPSYNC is set to 1. The value is derived as follows: FLADJ_REF_CLK_FLADJ=((125000/ref_clk_period_integer)-(125000/ref_clk_period)) ref_clk_period where: the ref_clk_period_integer is the integer value of the ref_clk period obtained by truncating the decimal (fractional) value that is programmed in the GUCTL.REF_CLK_PERIOD field. the ref_clk_period is the ref_clk period including the fractional value. Examples: If the ref_clk is 24MHz then GUCTL.REF_CLK_PERIOD=41 GFLADJ.GLADJ_REFCLK_FLADJ=((125000/41)-(125000/41.6666))41.6666=2032 (ignoring the fractional value) If the ref_clk is 48MHz then GUCTL.REF_CLK_PERIOD=20 GFLADJ.GLADJ_REFCLK_FLADJ=((125000/20)-(125000/20.8333))20.8333=5208 (ignoring the fractional value)
  [7] GFLADJ_30MHZ_SDBND_SEL — GFLADJ_30MHZ_SDBND_SEL This field selects whether to use the input signal fladj_30mhz_reg or the GFLADJ.GFLADJ_30MHZ to adjust the frame length for the SOF/ITP. When this bit is set to:
    1=the controller uses the register field GFLADJ.GFLADJ_30MHZ value; 0=the controller uses the input signal fladj_30mhz_reg value
  [5:0] GFLADJ_30MHZ — GFLADJ_30MHZ This field indicates the value that is used for frame length adjustment instead of considering from the sideband input signal fladj_30mhz_reg. This enables post-silicon frame length adjustment in case the input signal fladj_30mhz_reg is connected to a wrong value or is not valid. For details on how to set this value, refer to section 5.2.4, 'Frame Length Adjustment Register (FLADJ),' of [xHCI].
